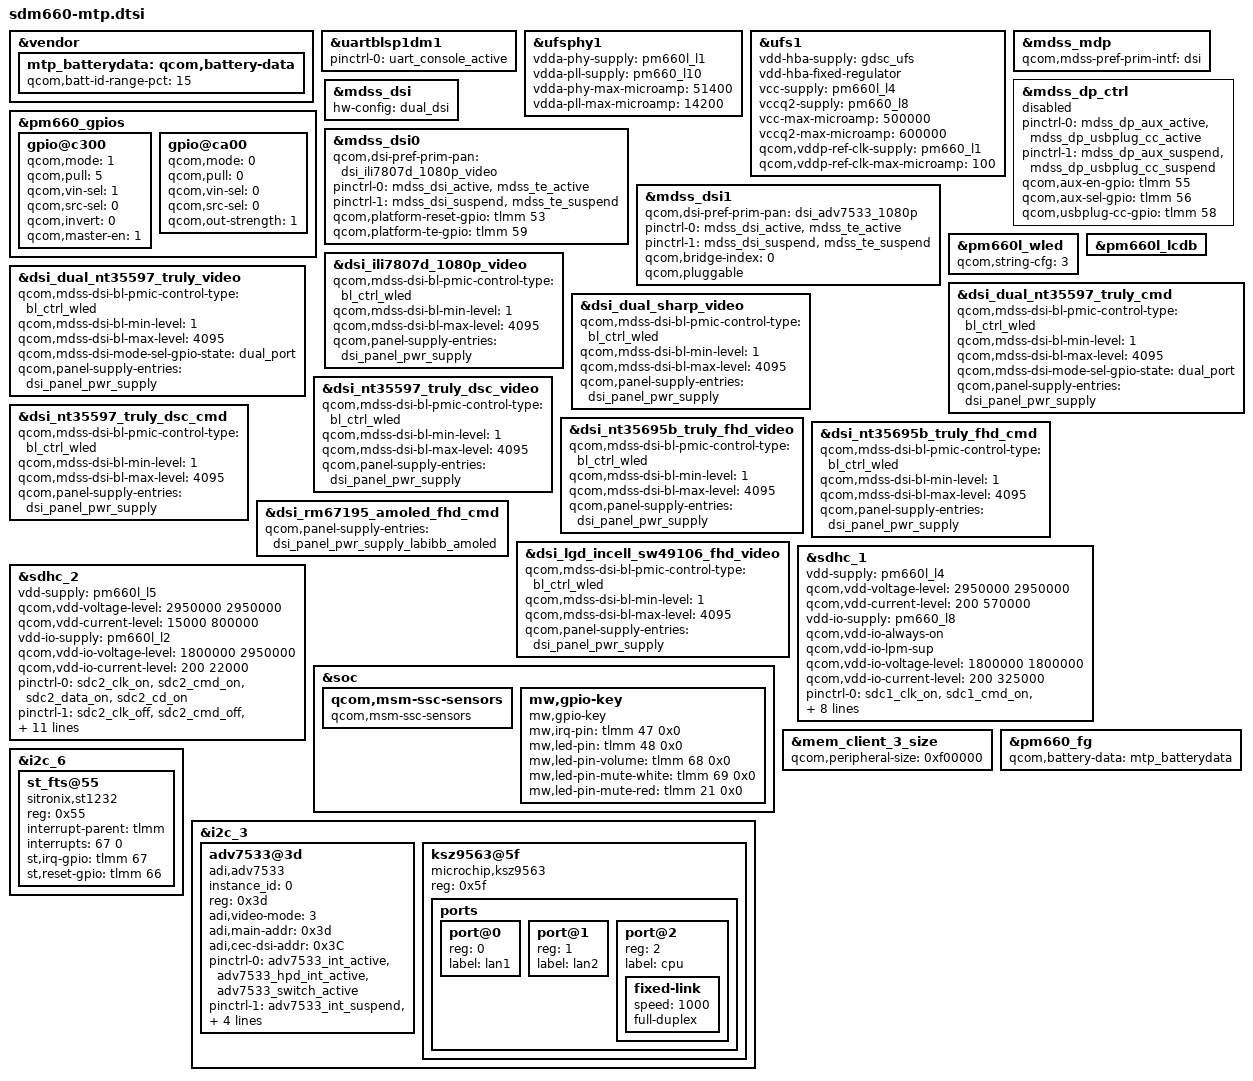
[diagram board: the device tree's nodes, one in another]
/* Copyright (c) 2016-2020, The Linux Foundation. All rights reserved.
 *
 * This program is free software; you can redistribute it and/or modify
 * it under the terms of the GNU General Public License version 2 and
 * only version 2 as published by the Free Software Foundation.
 *
 * This program is distributed in the hope that it will be useful,
 * but WITHOUT ANY WARRANTY; without even the implied warranty of
 * MERCHANTABILITY or FITNESS FOR A PARTICULAR PURPOSE.  See the
 * GNU General Public License for more details.
 */

#include "sdm660-camera-sensor-mtp.dtsi"

&vendor {
	mtp_batterydata: qcom,battery-data {
		qcom,batt-id-range-pct = <15>;
		#include "fg-gen3-batterydata-itech-3000mah.dtsi"
		#include "fg-gen3-batterydata-ascent-3450mah.dtsi"
	};
};

&uartblsp1dm1 {
	status = "ok";
	pinctrl-names = "default";
	pinctrl-0 = <&uart_console_active>;
};

&ufsphy1 {
	vdda-phy-supply = <&pm660l_l1>;
	vdda-pll-supply = <&pm660_l10>;
	vdda-phy-max-microamp = <51400>;
	vdda-pll-max-microamp = <14200>;
	status = "ok";
};

&ufs1 {
	vdd-hba-supply = <&gdsc_ufs>;
	vdd-hba-fixed-regulator;
	vcc-supply = <&pm660l_l4>;
	vccq2-supply = <&pm660_l8>;
	vcc-max-microamp = <500000>;
	vccq2-max-microamp = <600000>;
	qcom,vddp-ref-clk-supply = <&pm660_l1>;
	qcom,vddp-ref-clk-max-microamp = <100>;

	status = "ok";
};

&pm660_gpios {
	/* GPIO 4 (NFC_CLK_REQ) */
	gpio@c300 {
		qcom,mode = <1>;                /* Output */
		qcom,pull = <5>;                /* No Pull */
		qcom,vin-sel = <1>;             /* VIN1 GPIO_LV */
		qcom,src-sel = <0>;             /* GPIO */
		qcom,invert = <0>;              /* Invert */
		qcom,master-en = <1>;           /* Enable GPIO */
		status = "ok";
	};

	/* GPIO 11 for Home Key */
	gpio@ca00 {
		status = "okay";
		qcom,mode = <0>;
		qcom,pull = <0>;
		qcom,vin-sel = <0>;
		qcom,src-sel = <0>;
		qcom,out-strength = <1>;
	};
};

&mdss_mdp {
	qcom,mdss-pref-prim-intf = "dsi";
};

&mdss_dsi {
	hw-config = "dual_dsi";
};

&mdss_dsi0 {
	status = "ok";
	qcom,dsi-pref-prim-pan = <&dsi_ili7807d_1080p_video>;
	pinctrl-names = "mdss_default", "mdss_sleep";
	pinctrl-0 = <&mdss_dsi_active &mdss_te_active>;
	pinctrl-1 = <&mdss_dsi_suspend &mdss_te_suspend>;
	qcom,platform-reset-gpio = <&tlmm 53 0>;
	qcom,platform-te-gpio = <&tlmm 59 0>;
};

&mdss_dsi1 {
	qcom,dsi-pref-prim-pan = <&dsi_adv7533_1080p>;
	pinctrl-names = "mdss_default", "mdss_sleep";
	pinctrl-0 = <&mdss_dsi_active &mdss_te_active>;
	pinctrl-1 = <&mdss_dsi_suspend &mdss_te_suspend>;
	qcom,bridge-index = <0>;
	qcom,pluggable;
	/*qcom,platform-reset-gpio = <&tlmm 53 0>;
	qcom,platform-te-gpio = <&tlmm 59 0>;
	qcom,platform-bklight-en-gpio = <&tlmm 59 0>;*/
	status = "ok";
};

&mdss_dp_ctrl {
	status = "disabled";
	pinctrl-names = "mdss_dp_active", "mdss_dp_sleep";
	pinctrl-0 = <&mdss_dp_aux_active &mdss_dp_usbplug_cc_active>;
	pinctrl-1 = <&mdss_dp_aux_suspend &mdss_dp_usbplug_cc_suspend>;
	qcom,aux-en-gpio = <&tlmm 55 0>;
	qcom,aux-sel-gpio = <&tlmm 56 0>;
	qcom,usbplug-cc-gpio = <&tlmm 58 0>;
};

&pm660l_wled {
	qcom,string-cfg= <3>;
	status = "ok";
};

&pm660l_lcdb {
	status = "ok";
};

&dsi_ili7807d_1080p_video {
	qcom,mdss-dsi-bl-pmic-control-type = "bl_ctrl_wled";
	qcom,mdss-dsi-bl-min-level = <1>;
	qcom,mdss-dsi-bl-max-level = <4095>;
	qcom,panel-supply-entries = <&dsi_panel_pwr_supply>;
};

&dsi_dual_nt35597_truly_video {
	qcom,mdss-dsi-bl-pmic-control-type = "bl_ctrl_wled";
	qcom,mdss-dsi-bl-min-level = <1>;
	qcom,mdss-dsi-bl-max-level = <4095>;
	qcom,mdss-dsi-mode-sel-gpio-state = "dual_port";
	qcom,panel-supply-entries = <&dsi_panel_pwr_supply>;
};

&dsi_dual_nt35597_truly_cmd {
	qcom,mdss-dsi-bl-pmic-control-type = "bl_ctrl_wled";
	qcom,mdss-dsi-bl-min-level = <1>;
	qcom,mdss-dsi-bl-max-level = <4095>;
	qcom,mdss-dsi-mode-sel-gpio-state = "dual_port";
	qcom,panel-supply-entries = <&dsi_panel_pwr_supply>;
};

&dsi_dual_sharp_video {
	qcom,mdss-dsi-bl-pmic-control-type = "bl_ctrl_wled";
	qcom,mdss-dsi-bl-min-level = <1>;
	qcom,mdss-dsi-bl-max-level = <4095>;
	qcom,panel-supply-entries = <&dsi_panel_pwr_supply>;
};

&dsi_nt35597_truly_dsc_video {
	qcom,mdss-dsi-bl-pmic-control-type = "bl_ctrl_wled";
	qcom,mdss-dsi-bl-min-level = <1>;
	qcom,mdss-dsi-bl-max-level = <4095>;
	qcom,panel-supply-entries = <&dsi_panel_pwr_supply>;
};

&dsi_nt35597_truly_dsc_cmd {
	qcom,mdss-dsi-bl-pmic-control-type = "bl_ctrl_wled";
	qcom,mdss-dsi-bl-min-level = <1>;
	qcom,mdss-dsi-bl-max-level = <4095>;
	qcom,panel-supply-entries = <&dsi_panel_pwr_supply>;
};

&dsi_nt35695b_truly_fhd_video {
	qcom,mdss-dsi-bl-pmic-control-type = "bl_ctrl_wled";
	qcom,mdss-dsi-bl-min-level = <1>;
	qcom,mdss-dsi-bl-max-level = <4095>;
	qcom,panel-supply-entries = <&dsi_panel_pwr_supply>;
};

&dsi_nt35695b_truly_fhd_cmd {
	qcom,mdss-dsi-bl-pmic-control-type = "bl_ctrl_wled";
	qcom,mdss-dsi-bl-min-level = <1>;
	qcom,mdss-dsi-bl-max-level = <4095>;
	qcom,panel-supply-entries = <&dsi_panel_pwr_supply>;
};

&dsi_rm67195_amoled_fhd_cmd {
	qcom,panel-supply-entries = <&dsi_panel_pwr_supply_labibb_amoled>;
};

&dsi_lgd_incell_sw49106_fhd_video {
	qcom,mdss-dsi-bl-pmic-control-type = "bl_ctrl_wled";
	qcom,mdss-dsi-bl-min-level = <1>;
	qcom,mdss-dsi-bl-max-level = <4095>;
	qcom,panel-supply-entries = <&dsi_panel_pwr_supply>;
};

&sdhc_1 {
	/* device core power supply */
	vdd-supply = <&pm660l_l4>;
	qcom,vdd-voltage-level = <2950000 2950000>;
	qcom,vdd-current-level = <200 570000>;

	/* device communication power supply */
	vdd-io-supply = <&pm660_l8>;
	qcom,vdd-io-always-on;
	qcom,vdd-io-lpm-sup;
	qcom,vdd-io-voltage-level = <1800000 1800000>;
	qcom,vdd-io-current-level = <200 325000>;

	pinctrl-names = "active", "sleep";
	pinctrl-0 = <&sdc1_clk_on &sdc1_cmd_on &sdc1_data_on &sdc1_rclk_on>;
	pinctrl-1 = <&sdc1_clk_off &sdc1_cmd_off &sdc1_data_off &sdc1_rclk_off>;

	qcom,clk-rates = <400000 20000000 25000000 50000000 100000000 192000000
								384000000>;

	qcom,nonremovable;
	qcom,bus-speed-mode = "HS400_1p8v", "HS200_1p8v", "DDR_1p8v";

	status = "ok";
};

&sdhc_2 {
	/* device core power supply */
	vdd-supply = <&pm660l_l5>;
	qcom,vdd-voltage-level = <2950000 2950000>;
	qcom,vdd-current-level = <15000 800000>;

	/* device communication power supply */
	vdd-io-supply = <&pm660l_l2>;
	qcom,vdd-io-voltage-level = <1800000 2950000>;
	qcom,vdd-io-current-level = <200 22000>;

	pinctrl-names = "active", "sleep";
	pinctrl-0 = <&sdc2_clk_on &sdc2_cmd_on &sdc2_data_on &sdc2_cd_on>;
	pinctrl-1 = <&sdc2_clk_off &sdc2_cmd_off &sdc2_data_off &sdc2_cd_off>;

	#address-cells = <0>;
	interrupt-parent = <&sdhc_2>;
	interrupts = <0 1 2>;
	#interrupt-cells = <1>;
	interrupt-map-mask = <0xffffffff>;
	interrupt-map = <0 &intc 0 0 125 0
			1 &intc 0 0 221 0
			2 &tlmm 54 0>;
	interrupt-names = "hc_irq", "pwr_irq", "status_irq";
	cd-gpios = <&tlmm 54 0x1>;

	qcom,clk-rates = <400000 20000000 25000000 50000000 100000000
								200000000>;
	qcom,bus-speed-mode = "SDR12", "SDR25", "SDR50", "DDR50", "SDR104";

	status = "ok";
};

&soc {
	qcom,msm-ssc-sensors {
		compatible = "qcom,msm-ssc-sensors";
	};
	mw,gpio-key{
		compatible = "mw,gpio-key";
		mw,irq-pin = <&tlmm 47 0x0>;
		mw,led-pin = <&tlmm 48 0x0>;
		mw,led-pin-volume = <&tlmm 68 0x0>;
		mw,led-pin-mute-white = <&tlmm 69 0x0>;
		mw,led-pin-mute-red = <&tlmm 21 0x0>;
	};
};

&mem_client_3_size {
	qcom,peripheral-size = <0xf00000>;
};

&pm660_fg {
	qcom,battery-data = <&mtp_batterydata>;
};

&i2c_6 {
	st_fts@55 {
		status = "ok";
		compatible = "sitronix,st1232";
		reg = <0x55>;
		interrupt-parent = <&tlmm>;
		interrupts = <67 0>;
		interrupt-names = "touch_irq";
		//pinctrl-names = "pmx_ts_active", "pmx_ts_suspend";
		//pinctrl-0 = <&ts_active>;
		//pinctrl-1 = <&ts_int_suspend &ts_reset_suspend>;
		st,irq-gpio = <&tlmm 67 0x0>;
		st,reset-gpio = <&tlmm 66 0x0>;
	};

};

&i2c_3 {
		adv7533@3d {
			compatible = "adi,adv7533";
			instance_id = <0>;
			reg = <0x3d>;
			adi,video-mode = <3>; /* 3 = 1080p */
			adi,main-addr = <0x3d>;
			adi,cec-dsi-addr = <0x3C>;
			/*adi,enable-audio;*/
			pinctrl-names = "pmx_adv7533_active",
				"pmx_adv7533_suspend";
			pinctrl-0 = <&adv7533_int_active
				&adv7533_hpd_int_active
				&adv7533_switch_active>;
			pinctrl-1 = <&adv7533_int_suspend
				&adv7533_hpd_int_suspend
				&adv7533_switch_suspend>;
			adi,irq-gpio = <&tlmm 77 0x0>;
			adi,hpd-irq-gpio = <&tlmm 80 0x0>;
			//adi,switch-gpio = <&tlmm 10 0x1>;
			//hpd-5v-en-supply = <&adv_vreg>;
			//qcom,supply-names = "hpd-5v-en";
			//qcom,min-voltage-level = <0>;
			//qcom,max-voltage-level = <0>;
			//qcom,enable-load = <0>;
			//qcom,disable-load = <0>;
			//qcom,post-on-sleep = <10>;
		};

		ksz9563@5f {
		status = "ok";
		compatible = "microchip,ksz9563";
		reg = <0x5f>;
		ports {
			#address-cells = <1>;
			#size-cells = <0>;
			port@0 {
				reg = <0>;
				label = "lan1";
			};
			port@1 {
				reg = <1>;
				label = "lan2";
			};
			port@2 {
				reg = <2>;
				label = "cpu";
				/*ethernet = <&macb0>;*/
				fixed-link {
					speed = <1000>;
					full-duplex;
				};
			};
		};
	};
};
